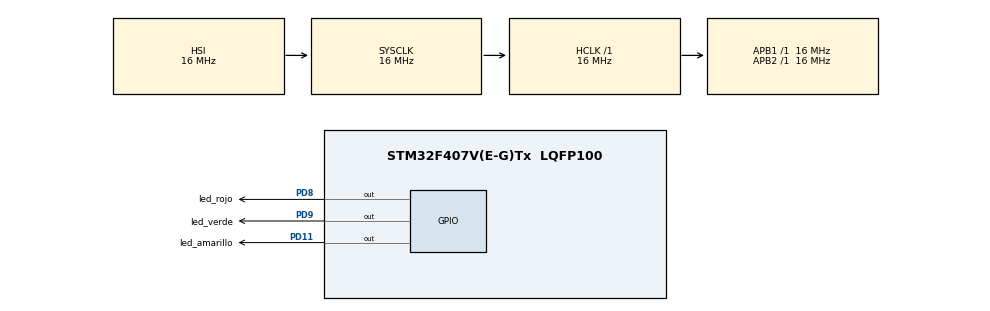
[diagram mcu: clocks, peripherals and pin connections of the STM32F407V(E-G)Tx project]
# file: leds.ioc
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FREERTOS.Tasks01=defaultTask,24,128,StartDefaultTask,Default,NULL,Dynamic,NULL,NULL
Mcu.Family=STM32F4
Mcu.Name=STM32F407V(E-G)Tx
Mcu.Package=LQFP100
NVIC.PriorityGroup=NVIC_PRIORITYGROUP_4
NVIC.TIM1_UP_TIM10_IRQn=true\:15\:0\:false\:false\:true\:false\:false\:true\:true
NVIC.TimeBase=TIM1_UP_TIM10_IRQn
NVIC.TimeBaseIP=TIM1
PD11.GPIO_Label=led_amarillo
PD11.Signal=GPIO_Output
PD8.GPIO_Label=led_rojo
PD8.Signal=GPIO_Output
PD9.GPIO_Label=led_verde
PD9.Signal=GPIO_Output
ProjectManager.HeapSize=0x200
ProjectManager.StackSize=0x400
ProjectManager.TargetToolchain=STM32CubeIDE
RCC.AHBFreq_Value=16000000
RCC.APB1Freq_Value=16000000
RCC.APB2Freq_Value=16000000
RCC.CortexFreq_Value=16000000
RCC.HSE_VALUE=25000000
RCC.HSI_VALUE=16000000
RCC.LSE_VALUE=32768
RCC.SYSCLKFreq_VALUE=16000000
RCC.VCOOutputFreq_Value=192000000
VP_FREERTOS_VS_CMSIS_V2.Mode=CMSIS_V2
VP_SYS_VS_tim1.Mode=TIM1
board=custom

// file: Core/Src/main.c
/* USER CODE BEGIN Header */
/**
  ******************************************************************************
  * @file           : main.c
  * @brief          : Main program body
  ******************************************************************************
  * @attention
  *
  * Copyright (c) 2026 STMicroelectronics.
  * All rights reserved.
  *
  * This software is licensed under terms that can be found in the LICENSE file
  * in the root directory of this software component.
  * If no LICENSE file comes with this software, it is provided AS-IS.
  *
  ******************************************************************************
  */
/* USER CODE END Header */
#include "main.h"
#include "cmsis_os.h"

/* USER CODE BEGIN Includes */
#include "led.h"
/* USER CODE END Includes */

/* Definitions for defaultTask */
osThreadId_t defaultTaskHandle;
const osThreadAttr_t defaultTask_attributes = {
  .name = "defaultTask",
  .stack_size = 128 * 4,
  .priority = (osPriority_t) osPriorityNormal,
};
/* USER CODE BEGIN PV */
osThreadId_t taskToggleLedRojo;
osThreadId_t taskToggleLedVerde;
osThreadId_t taskToggleLedAmarillo;
const osThreadAttr_t toggleLedTask_attributes = {
  .name = "toggleLedTask",
  .stack_size = 128 * 4,
  .priority = (osPriority_t) osPriorityNormal1,
};
const osThreadAttr_t toggleLedTask_highPriority_attributes = {
  .name = "toggleLedTask",
  .stack_size = 128 * 4,
  .priority = (osPriority_t) osPriorityHigh,
};
/* USER CODE END PV */

void SystemClock_Config(void);
static void MX_GPIO_Init(void);
void StartDefaultTask(void *argument);

/* USER CODE BEGIN PFP */
void toggleLedDelay(void* void_led)
{
	Led* led = (Led*)void_led;
	int unsigned wait_time = 1000/(led->frecuency_toggle*2); //[ms]

	while(1)
	{
		led_toggle(led);
		osDelay(pdMS_TO_TICKS(wait_time));
	}
}

void toggleLedUntil(void* void_led)
{
	Led* led = (Led*)void_led;
	int unsigned wait_time = 1000/(led->frecuency_toggle*2); //[ms]
	uint32_t wait_ticks = pdMS_TO_TICKS(wait_time);

	uint32_t next_tick = osKernelGetTickCount();

	while(1)
	{
		next_tick += wait_ticks;
		led_toggle(led);
		osDelayUntil(next_tick);
	}
}
void toggleLedActiveWait(void* void_led)
{
	Led* led = (Led*)void_led;
	int unsigned wait_time = 1000/(led->frecuency_toggle*2); //[ms]

	while(1)
	{
		led_toggle(led);
		HAL_Delay(wait_time);
	}
}
/* USER CODE END PFP */

/* USER CODE BEGIN 0 */
Led led_rojo;
Led led_amarillo;
Led led_verde;
/* USER CODE END 0 */

int main(void)
{

  /* MCU Configuration--------------------------------------------------------*/

  /* Reset of all peripherals, Initializes the Flash interface and the Systick. */
  HAL_Init();

  /* Configure the system clock */
  SystemClock_Config();

  /* Initialize all configured peripherals */
  MX_GPIO_Init();
  /* USER CODE BEGIN 2 */
  led_rojo = led_new(led_rojo_GPIO_Port, led_rojo_Pin, 1);
  led_amarillo = led_new(led_amarillo_GPIO_Port, led_amarillo_Pin, 1);
  led_verde = led_new(led_verde_GPIO_Port, led_verde_Pin, 1);
  /* USER CODE END 2 */

  /* Init scheduler */
  osKernelInitialize();

  /* Create the thread(s) */
  /* creation of defaultTask */
  defaultTaskHandle = osThreadNew(StartDefaultTask, NULL, &defaultTask_attributes);

  /* USER CODE BEGIN RTOS_THREADS */
  taskToggleLedRojo = osThreadNew(toggleLedUntil, (void*)&led_rojo, &toggleLedTask_attributes);
  taskToggleLedAmarillo = osThreadNew(toggleLedDelay, (void*)&led_amarillo, &toggleLedTask_attributes);
  taskToggleLedVerde = osThreadNew(toggleLedActiveWait, (void*)&led_verde, &toggleLedTask_attributes);
  /* USER CODE END RTOS_THREADS */

  /* Start scheduler */
  osKernelStart();

  /* We should never get here as control is now taken by the scheduler */

  /* Infinite loop */
  while (1)
  {

  }
}

void SystemClock_Config(void)
{
  RCC_OscInitTypeDef RCC_OscInitStruct = {0};
  RCC_ClkInitTypeDef RCC_ClkInitStruct = {0};

  /** Configure the main internal regulator output voltage
  */
  __HAL_RCC_PWR_CLK_ENABLE();
  __HAL_PWR_VOLTAGESCALING_CONFIG(PWR_REGULATOR_VOLTAGE_SCALE1);

  /** Initializes the RCC Oscillators according to the specified parameters
  * in the RCC_OscInitTypeDef structure.
  */
  RCC_OscInitStruct.OscillatorType = RCC_OSCILLATORTYPE_HSI;
  RCC_OscInitStruct.HSIState = RCC_HSI_ON;
  RCC_OscInitStruct.HSICalibrationValue = RCC_HSICALIBRATION_DEFAULT;
  RCC_OscInitStruct.PLL.PLLState = RCC_PLL_NONE;
  if (HAL_RCC_OscConfig(&RCC_OscInitStruct) != HAL_OK)
  {
    Error_Handler();
  }

  /** Initializes the CPU, AHB and APB buses clocks
  */
  RCC_ClkInitStruct.ClockType = RCC_CLOCKTYPE_HCLK|RCC_CLOCKTYPE_SYSCLK
                              |RCC_CLOCKTYPE_PCLK1|RCC_CLOCKTYPE_PCLK2;
  RCC_ClkInitStruct.SYSCLKSource = RCC_SYSCLKSOURCE_HSI;
  RCC_ClkInitStruct.AHBCLKDivider = RCC_SYSCLK_DIV1;
  RCC_ClkInitStruct.APB1CLKDivider = RCC_HCLK_DIV1;
  RCC_ClkInitStruct.APB2CLKDivider = RCC_HCLK_DIV1;

  if (HAL_RCC_ClockConfig(&RCC_ClkInitStruct, FLASH_LATENCY_0) != HAL_OK)
  {
    Error_Handler();
  }
}

static void MX_GPIO_Init(void)
{
  GPIO_InitTypeDef GPIO_InitStruct = {0};

  /* GPIO Ports Clock Enable */
  __HAL_RCC_GPIOD_CLK_ENABLE();

  /*Configure GPIO pin Output Level */
  HAL_GPIO_WritePin(GPIOD, led_rojo_Pin|led_verde_Pin|led_amarillo_Pin, GPIO_PIN_RESET);

  /*Configure GPIO pins : led_rojo_Pin led_verde_Pin led_amarillo_Pin */
  GPIO_InitStruct.Pin = led_rojo_Pin|led_verde_Pin|led_amarillo_Pin;
  GPIO_InitStruct.Mode = GPIO_MODE_OUTPUT_PP;
  GPIO_InitStruct.Pull = GPIO_NOPULL;
  GPIO_InitStruct.Speed = GPIO_SPEED_FREQ_LOW;
  HAL_GPIO_Init(GPIOD, &GPIO_InitStruct);

}

void StartDefaultTask(void *argument)
{
  for(;;)
  {
    osDelay(1);
  }
}

void HAL_TIM_PeriodElapsedCallback(TIM_HandleTypeDef *htim)
{
  if (htim->Instance == TIM1)
  {
    HAL_IncTick();
  }
}

void Error_Handler(void)
{
  __disable_irq();
  while (1)
  {
  }
}
